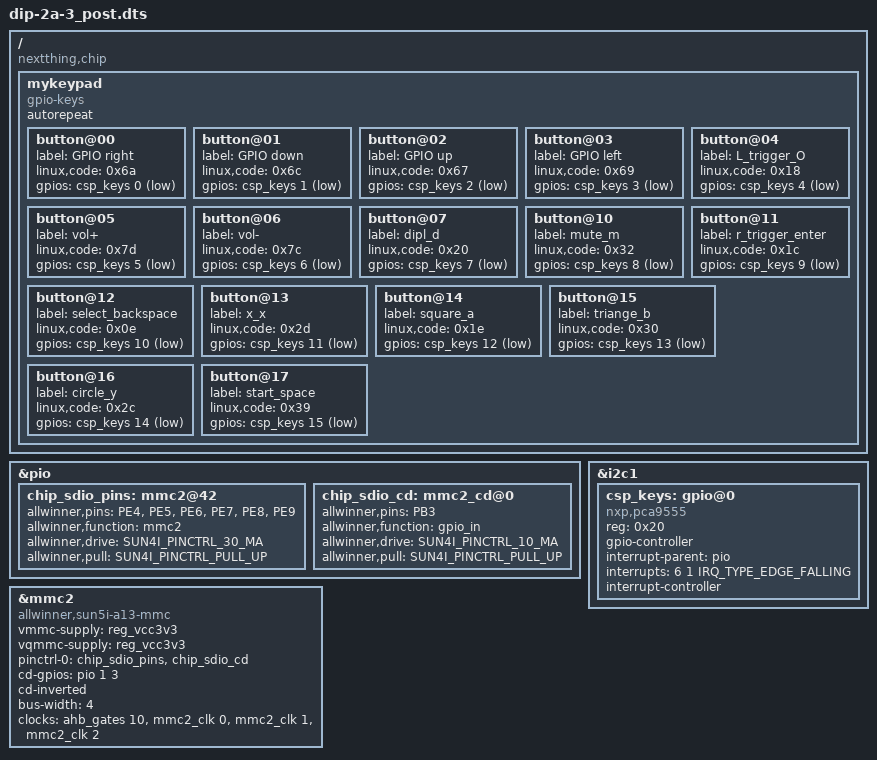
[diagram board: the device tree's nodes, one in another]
/*
* Copyright 2016
* Kolja Windeler <kolja.windeler@gmail.com>
*
*
* This file is dual-licensed: you can use it either under the terms
* of the GPL or the X11 license, at your option. Note that this dual
* licensing only applies to this file, and not this project as a
* whole.
*
* a) This file is free software; you can redistribute it and/or
* modify it under the terms of the GNU General Public License as
* published by the Free Software Foundation; either version 2 of the
* License, or (at your option) any later version.
*
* This file is distributed in the hope that it will be useful,
* but WITHOUT ANY WARRANTY; without even the implied warranty of
* MERCHANTABILITY or FITNESS FOR A PARTICULAR PURPOSE. See the
* GNU General Public License for more details.
*
* Or, alternatively,
*
* b) Permission is hereby granted, free of charge, to any person
* obtaining a copy of this software and associated documentation
* files (the "Software"), to deal in the Software without
* restriction, including without limitation the rights to use,
* copy, modify, merge, publish, distribute, sublicense, and/or
* sell copies of the Software, and to permit persons to whom the
* Software is furnished to do so, subject to the following
* conditions:
*
* The above copyright notice and this permission notice shall be
* included in all copies or substantial portions of the Software.
*
* THE SOFTWARE IS PROVIDED "AS IS", WITHOUT WARRANTY OF ANY KIND,
* EXPRESS OR IMPLIED, INCLUDING BUT NOT LIMITED TO THE WARRANTIES
* OF MERCHANTABILITY, FITNESS FOR A PARTICULAR PURPOSE AND
* NONINFRINGEMENT. IN NO EVENT SHALL THE AUTHORS OR COPYRIGHT
* HOLDERS BE LIABLE FOR ANY CLAIM, DAMAGES OR OTHER LIABILITY,
* WHETHER IN AN ACTION OF CONTRACT, TORT OR OTHERWISE, ARISING
* FROM, OUT OF OR IN CONNECTION WITH THE SOFTWARE OR THE USE OR
* OTHER DEALINGS IN THE SOFTWARE.
*/
/dts-v1/;
/plugin/;
#include <dt-bindings/pinctrl/sun4i-a10.h>
#include <dt-bindings/gpio/gpio.h>
#include <dt-bindings/input/input.h>
#include <dt-bindings/interrupt-controller/irq.h>
/ {
	compatible = "nextthing,chip", "allwinner,sun5i-r8";
	
	/* 	 Enable our SDIO pins		 */
	fragment@0 {
		target = <&pio>;		
		__overlay__ {

			chip_sdio_pins: mmc2@42 {
				allwinner,pins = "PE4", "PE5", "PE6", "PE7", "PE8", "PE9";
				allwinner,function = "mmc2";
				allwinner,drive = <SUN4I_PINCTRL_30_MA>;
				allwinner,pull = <SUN4I_PINCTRL_PULL_UP>;
			};

			chip_sdio_cd: mmc2_cd@0 {
				allwinner,pins = "PB3";
				allwinner,function = "gpio_in";
				allwinner,drive = <SUN4I_PINCTRL_10_MA>;
				allwinner,pull = <SUN4I_PINCTRL_PULL_UP>;
			};
			
		};
	};


	/*	 Enable our SDIO device	 */
	fragment@1 {
		target = <&mmc2 >;

		__overlay__ {
			vmmc-supply = <&reg_vcc3v3>;
			vqmmc-supply = <&reg_vcc3v3>;
			// everything below this like is default, but I'll set it to be sure
			pinctrl-names = "default";
			compatible = "allwinner,sun5i-a13-mmc";
			pinctrl-0 = <&chip_sdio_pins>,  <&chip_sdio_cd>;
			cd-gpios = <&pio 1 3 GPIO_ACTIVE_HIGH>;
			cd-inverted; // it is low active, but this is somehow wrong
			bus-width = <4>;
                        clocks = <&ahb_gates 10>,<&mmc2_clk 0>,<&mmc2_clk 1>,<&mmc2_clk 2>;
			// and go!
			status = "okay";
		};
	};

	// enabled pin expander on i2c1
	fragment@3 {
		target = <&i2c1>;
		__overlay__ {
			#address-cells = <1>; // one 32bit value for reg
			#size-cells = <0>; // no size value following the address in reg
			csp_keys:gpio@0 {
				compatible = "nxp,pca9555";
				reg = <0x20>;

				gpio-controller;
				#gpio-cells = <2>;

				interrupt-parent = <&pio>;
				interrupts = <6 1 IRQ_TYPE_EDGE_FALLING>; // "PG1"
				interrupt-controller;
				#interrupt-cells = <2>;
			};
		};
	};

	// enable keyboard
	fragment@4 {
		target-path = "/";
		__overlay__ {
			mykeypad: mykeypad {
				compatible = "gpio-keys";
				autorepeat;
				#address-cells = <1>;
				#size-cells = <0>;
				
				// define buttons
				button@00 {
					label = "GPIO right";
					linux,code = <0x6a>; // hex
					gpios = <&csp_keys 0 GPIO_ACTIVE_LOW>; // pin 0.0, "1>" = active_low
				};
				button@01 {
					label = "GPIO down";
					linux,code = <0x6c>;
					gpios = <&csp_keys 1 GPIO_ACTIVE_LOW>; // pin 0.1, active_low
				};
				button@02 {
					label = "GPIO up";
					linux,code = <0x67>;
					gpios = <&csp_keys 2 GPIO_ACTIVE_LOW>; // pin 0.2, active_low
				};
				button@03 {
					label = "GPIO left";
					linux,code = <0x69>;
					gpios = <&csp_keys 3 GPIO_ACTIVE_LOW>; // pin 0.3, active_low
				};
				button@04 {
					label = "L_trigger_O";
					linux,code = <0x18>; 
					gpios = <&csp_keys 4 GPIO_ACTIVE_LOW>; // pin 0.4, active_low
				};
				button@05 {
					label = "vol+";
					linux,code = <0x7d>;
					gpios = <&csp_keys 5 GPIO_ACTIVE_LOW>; // pin 0.5, active_low
				};
				button@06 {
					label = "vol-";
					linux,code = <0x7c>;
					gpios = <&csp_keys 6 GPIO_ACTIVE_LOW>; // pin 0.6, active_low
				};
				button@07 {
					label = "dipl_d";
					linux,code = <0x20>;
					gpios = <&csp_keys 7 GPIO_ACTIVE_LOW>; // pin 0.7, active_low
				};
				button@10 {
					label = "mute_m";
					linux,code = <0x32>; // hex
					gpios = <&csp_keys 8 GPIO_ACTIVE_LOW>; // pin 1.0, active_low
				};
				button@11 {
					label = "r_trigger_enter";
					linux,code = <0x1c>;
					gpios = <&csp_keys 9 GPIO_ACTIVE_LOW>; // pin 1.1, active_low
				};
				button@12 {
					label = "select_backspace";
					linux,code = <0x0e>;
					gpios = <&csp_keys 10 GPIO_ACTIVE_LOW>; // pin 1.2, active_low
				};
				button@13 {
					label = "x_x";
					linux,code = <0x2d>;
					gpios = <&csp_keys 11 GPIO_ACTIVE_LOW>; // pin 1.3, active_low
				};
				button@14 {
					label = "square_a";
					linux,code = <0x1e>;
					gpios = <&csp_keys 12 GPIO_ACTIVE_LOW>; // pin 1.4, active_low
				};
				button@15 {
					label = "triange_b";
					linux,code = <0x30>;
					gpios = <&csp_keys 13 GPIO_ACTIVE_LOW>; // pin 1.5, active_low
				};
				button@16 {
					label = "circle_y";
					linux,code = <0x2c>;
					gpios = <&csp_keys 14 GPIO_ACTIVE_LOW>; // pin 1.6, active_low
				};
				button@17 {
					label = "start_space";
					linux,code = <0x39>;
					gpios = <&csp_keys 15 GPIO_ACTIVE_LOW>; // pin 1.7, active_low
				};
			};
		};
	};


};
